# STM32U5A5 register map
File version: 1.0
CPU: CM33 r0p1, little endian, MPU, FPU, 4 interrupt priority bits
Registers are 32-bit, read-write, reset 0x0 unless marked. A register's access mark holds for its fields unless they carry their own. Offsets are from the block's base; [hi:lo] are bit positions; {n}, {i} and the like mark numbered series; 'fields as' and 'values as' point back to an identical list.

## TAMP — Tamper and backup registers
Base 0x46007C00
Same registers: SEC_TAMP 0x56007C00
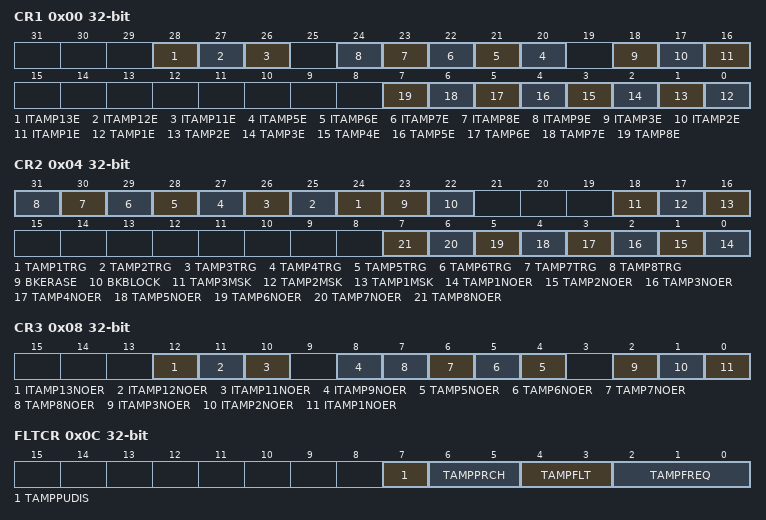
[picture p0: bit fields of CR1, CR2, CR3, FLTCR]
0x00 CR1 — control register 1
  [28] ITAMP13E
  [27] ITAMP12E
  [26] ITAMP11E — TAMP1E
  [n+15] ITAMP{n}E (n=5..9)
  [18] ITAMP3E
  [17] ITAMP2E
  [16] ITAMP1E
  [n-1] TAMP{n}E (n=1..8)
0x04 CR2 — control register 2
  [n+23] TAMP{n}TRG (n=1..8), [23] BKERASE, [22] BKBLOCK, [18] TAMP3MSK, [17] TAMP2MSK, [16] TAMP1MSK, [n-1] TAMP{n}NOER (n=1..8)
0x08 CR3 — control register 3
  [12] ITAMP13NOER, [11] ITAMP12NOER, [10] ITAMP11NOER, [8] ITAMP9NOER, [n-1] TAMP{n}NOER (n=5..8), [2] ITAMP3NOER, [1] ITAMP2NOER, [0] ITAMP1NOER
0x0C FLTCR — TAMP filter control register
  [7] TAMPPUDIS, [6:5] TAMPPRCH, [4:3] TAMPFLT, [2:0] TAMPFREQ
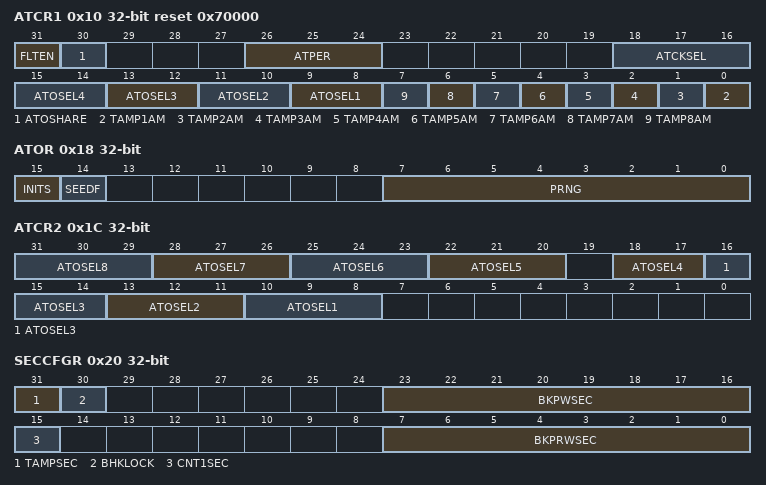
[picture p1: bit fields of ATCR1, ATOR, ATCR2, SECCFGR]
0x10 ATCR1 reset 0x70000 — TAMP active tamper control register
  [31] FLTEN — ATOSHARE
  [30] ATOSHARE
  [26:24] ATPER
  [18:16] ATCKSEL
  [2n+7:2n+6] ATOSEL{n} (n=1..4)
  [n-1] TAMP{n}AM (n=1..8)
0x14 ATSEEDR — TAMP active tamper seed register
  [31:0] SEED
0x18 ATOR ro — TAMP active tamper output register
  [15] INITS, [14] SEEDF, [7:0] PRNG
0x1C ATCR2 — TAMP active tamper control register 2
  [3n+7:3n+5] ATOSEL{n} (n=5..8), [18:17] ATOSEL4, [16:14] ATOSEL3, [13:11] ATOSEL2, [10:8] ATOSEL1
0x20 SECCFGR — TAMP secure mode register
  [31] TAMPSEC, [30] BHKLOCK, [23:16] BKPWSEC, [15] CNT1SEC, [7:0] BKPRWSEC
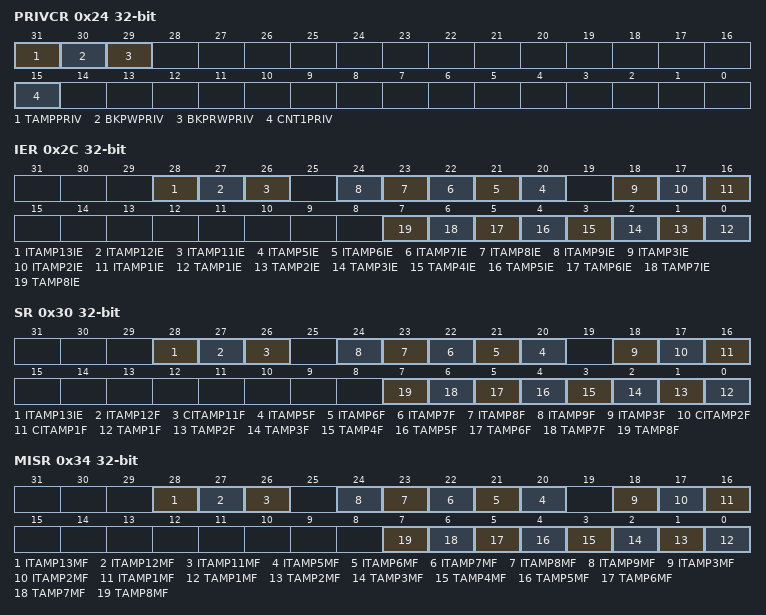
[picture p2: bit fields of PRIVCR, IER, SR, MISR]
0x24 PRIVCR — TAMP privilege mode control register
  [31] TAMPPRIV, [30] BKPWPRIV, [29] BKPRWPRIV, [15] CNT1PRIV
0x2C IER — TAMP interrupt enable register
  [28] ITAMP13IE, [27] ITAMP12IE, [26] ITAMP11IE, [n+15] ITAMP{n}IE (n=5..9), [18] ITAMP3IE, [17] ITAMP2IE, [16] ITAMP1IE, [n-1] TAMP{n}IE (n=1..8)
0x30 SR ro — TAMP status register
  [28] ITAMP13IE, [27] ITAMP12F, [26] CITAMP11F, [n+15] ITAMP{n}F (n=5..9), [18] ITAMP3F, [17] CITAMP2F, [16] CITAMP1F, [n-1] TAMP{n}F (n=1..8)
0x34 MISR ro — TAMP masked interrupt status register
  [28] ITAMP13MF, [27] ITAMP12MF, [26] ITAMP11MF, [n+15] ITAMP{n}MF (n=5..9), [18] ITAMP3MF, [17] ITAMP2MF, [16] ITAMP1MF, [n-1] TAMP{n}MF (n=1..8)
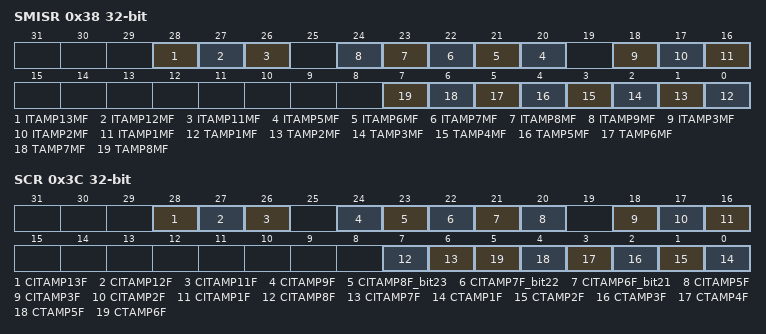
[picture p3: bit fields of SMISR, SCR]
0x38 SMISR ro — TAMP secure masked interrupt status register
  fields as MISR
0x3C SCR — TAMP status clear register
  [28] CITAMP13F
  [27] CITAMP12F
  [26] CITAMP11F
  [24] CITAMP9F
  [23] CITAMP8F_bit23
  [22] CITAMP7F_bit22
  [21] CITAMP6F_bit21
  [20] CITAMP5F
  [18] CITAMP3F
  [17] CITAMP2F
  [16] CITAMP1F
  [7] CITAMP8F — CITAMP3F
  [6] CITAMP7F — CITAMP3F
  [n-1] CTAMP{n}F (n=1..6)
0x40 COUNT1R ro — TAMP monotonic counter 1register
  [31:0] COUNT
0x54 ERCFGR — TAMP erase configuration register
  [0] ERCFG0
{0x100+4i} BKP{i}R (i=0..31) — TAMP backup register
  [31:0] BKP

## TIM6 — General-purpose-timers
Base 0x40001000
Same registers: TIM7 0x40001400, SEC_TIM6 0x50001000, SEC_TIM7 0x50001400
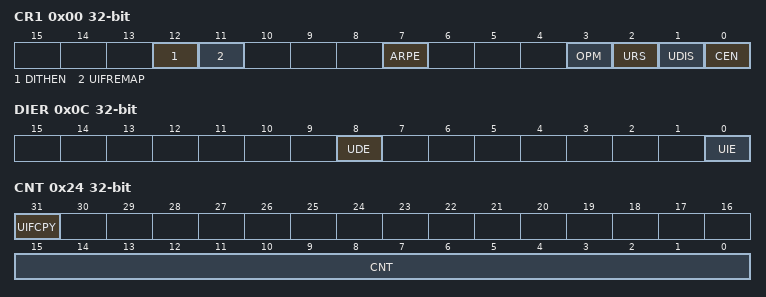
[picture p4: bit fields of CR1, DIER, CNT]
0x00 CR1 — control register 1
  [12] DITHEN — Dithering Enable
    0=Disabled (Dithering disabled); 1=Enabled (Dithering enabled)
  [11] UIFREMAP — UIF status bit remapping
    0=Disabled (No remapping. UIF status bit is not copied to TIMx_CNT register bit 31); 1=Enabled (Remapping enabled. UIF status bit is copied to TIMx_CNT register bit 31)
  [7] ARPE — Auto-reload preload enable
    0=Disabled (TIMx_APRR register is not buffered); 1=Enabled (TIMx_APRR register is buffered)
  [3] OPM — One-pulse mode
    0=Disabled (Counter is not stopped at update event); 1=Enabled (Counter stops counting at the next update event (clearing the CEN bit))
  [2] URS — Update request source
    0=AnyEvent (Any of counter overflow/underflow, setting UG, or update through slave mode, generates an update interrupt or DMA request); 1=CounterOnly (Only counter overflow/underflow generates an update interrupt or DMA request)
  [1] UDIS — Update disable
    0=Enabled (Update event enabled); 1=Disabled (Update event disabled)
  [0] CEN — Counter enable
    0=Disabled (Counter disabled); 1=Enabled (Counter enabled)
0x04 CR2 — control register 2
  [6:4] MMS — Master mode selection
    0=Reset (Use UG bit from TIMx_EGR register); 1=Enable (Use CNT bit from TIMx_CEN register); 2=Update (Use the update event)
0x0C DIER — DMA/Interrupt enable register
  [8] UDE
    0=Disabled (Update DMA request disabled); 1=Enabled (Update DMA request enabled)
  [0] UIE
    0=Disabled (Update interrupt disabled); 1=Enabled (Update interrupt enabled)
0x10 SR — status register
  [0] UIF write-0-clears
    on read: 0=NoUpdateOccurred; 1=UpdatePending (Update interrupt pending) | on write: 0=Clear flag
0x14 EGR wo — event generation register
  [0] UG
    1=Update (Re-initializes the timer counter and generates an update of the registers.)
0x24 CNT — counter
  [31] UIFCPY
    on read: 0=NoUpdateOccurred; 1=UpdatePending (Update interrupt pending)
  [15:0] CNT
0x28 PSC — prescaler
  [15:0] PSC
0x2C ARR reset 0xFFFF — auto-reload register
  [19:0] ARR

## VREFBUF — Voltage reference buffer
Base 0x46007400
Same registers: SEC_VREFBUF 0x56007400
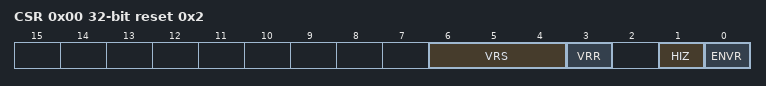
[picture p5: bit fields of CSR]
0x00 CSR access per field reset 0x2 — VREFBUF control and status register
  [6:4] VRS rw, [3] VRR ro, [1] HIZ rw, [0] ENVR rw
0x04 CCR — VREFBUF calibration control register
  [5:0] TRIM

## WWDG — System window watchdog
Base 0x40002C00
Same registers: SEC_WWDG 0x50002C00
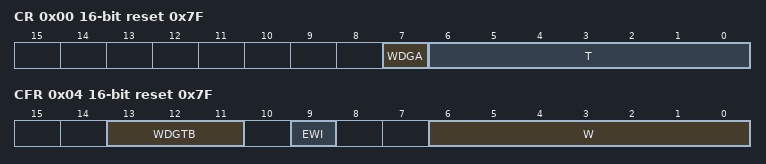
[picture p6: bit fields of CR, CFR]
0x00 CR 16-bit reset 0x7F — Control register
  [7] WDGA — Activation bit
    0=Disabled (Watchdog disabled); 1=Enabled (Watchdog enabled)
  [6:0] T — 7-bit counter (MSB to LSB)
0x04 CFR 16-bit reset 0x7F — Configuration register
  [13:11] WDGTB — Timer base
    0=Div1 (Counter clock (PCLK1 div 4096) div 1); 1=Div2 (Counter clock (PCLK1 div 4096) div 2); 2=Div4 (Counter clock (PCLK1 div 4096) div 4); 3=Div8 (Counter clock (PCLK1 div 4096) div 8); 4=Div16 (Counter clock (PCLK1 div 4096) div 16); 5=Div32 (Counter clock (PCLK1 div 4096) div 32); 6=Div64 (Counter clock (PCLK1 div 4096) div 64); 7=Div128 (Counter clock (PCLK1 div 4096) div 128)
  [9] EWI — Early wakeup interrupt
    on write: 1=Enable (interrupt occurs whenever the counter reaches the value 0x40)
  [6:0] W — 7-bit window value
0x08 SR 16-bit — Status register
  [0] EWIF write-0-clears — Early wakeup interrupt flag
    on read: 0=Finished (The EWI Interrupt Service Routine has been serviced); 1=Pending (The EWI Interrupt Service Routine has been triggered) | on write: 0=Finished (The EWI Interrupt Service Routine has been serviced)

## DCB — Debug Control Block
Base 0xE000EE08
0x00 DSCSR — Debug Security Control and Status Register
  [16] CDS — Current domain Secure
